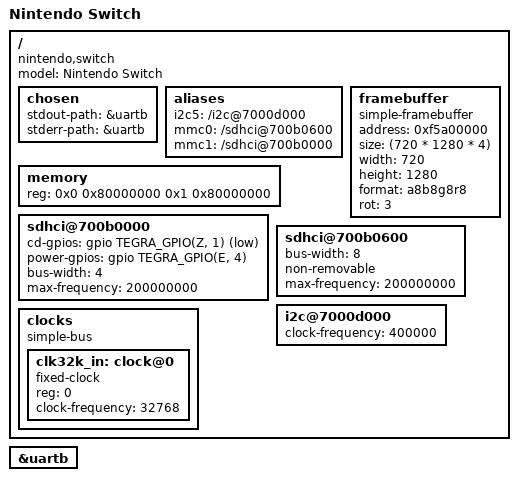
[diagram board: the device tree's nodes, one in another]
/dts-v1/;

#include "tegra210.dtsi"

/ {
	model = "Nintendo Switch";
	compatible = "nintendo,switch", "nvidia,tegra210";

	chosen {
		stdout-path = &uartb;
		stderr-path = &uartb;
	};

	aliases {
		i2c5 = "/i2c@7000d000";
		mmc0 = "/sdhci@700b0600";
		mmc1 = "/sdhci@700b0000";
	};

	memory {
		reg = <0x0 0x80000000 0x1 0x80000000>;
	};

	framebuffer {
		compatible = "simple-framebuffer";
		address = <0xf5a00000>;
		size = <(720 * 1280 * 4)>;
		width = <720>;
		height = <1280>;
		format = "a8b8g8r8";
		rot = <3>;
	};

	sdhci@700b0000 {
		status = "okay";
		cd-gpios = <&gpio TEGRA_GPIO(Z, 1) GPIO_ACTIVE_LOW>;
		power-gpios = <&gpio TEGRA_GPIO(E, 4) GPIO_ACTIVE_HIGH>;
		bus-width = <4>;
		max-frequency = <200000000>;
	};

	sdhci@700b0600 {
		status = "okay";
		bus-width = <8>;
		non-removable;
		max-frequency = <200000000>;
	};

	i2c@7000d000 {
		status = "okay";
		clock-frequency = <400000>;
	};

	clocks {
		compatible = "simple-bus";
		#address-cells = <1>;
		#size-cells = <0>;

		clk32k_in: clock@0 {
			compatible = "fixed-clock";
			reg = <0>;
			#clock-cells = <0>;
			clock-frequency = <32768>;
		};
	};
};

&uartb {
	status = "okay";
};
